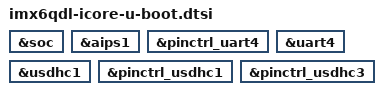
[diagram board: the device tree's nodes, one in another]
// SPDX-License-Identifier: GPL-2.0+
/*
 * Copyright (C) 2018 Jagan Teki <jagan@amarulasolutions.com>
 */

#include "imx6qdl-u-boot.dtsi"

&soc {
	bootph-all;
};

&aips1 {
	bootph-all;
};

&pinctrl_uart4 {
	bootph-all;
};

&uart4 {
	bootph-all;
};

&usdhc1 {
	bootph-pre-ram;
};

&pinctrl_usdhc1 {
	bootph-pre-ram;
};

&pinctrl_usdhc3 {
	bootph-pre-ram;
};
